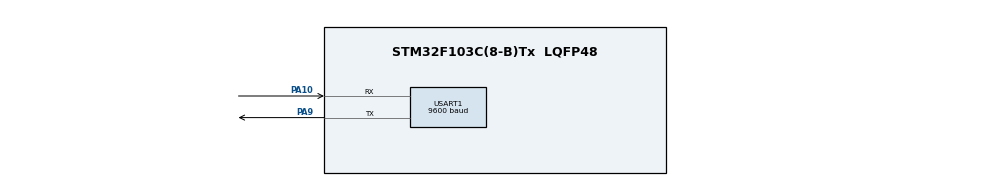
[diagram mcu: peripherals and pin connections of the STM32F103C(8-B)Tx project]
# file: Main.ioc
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Mcu.Family=STM32F1
Mcu.Name=STM32F103C(8-B)Tx
Mcu.Package=LQFP48
NVIC.PriorityGroup=NVIC_PRIORITYGROUP_4
NVIC.USART1_IRQn=true\:0\:0\:false\:false\:true\:true\:true\:true
PA10.Mode=Asynchronous
PA10.Signal=USART1_RX
PA13.Mode=Serial_Wire
PA13.Signal=SYS_JTMS-SWDIO
PA14.Mode=Serial_Wire
PA14.Signal=SYS_JTCK-SWCLK
PA9.Mode=Asynchronous
PA9.Signal=USART1_TX
ProjectManager.HeapSize=0x200
ProjectManager.StackSize=0x400
ProjectManager.TargetToolchain=MDK-ARM V5.27
RCC.APB1Freq_Value=8000000
RCC.APB2Freq_Value=8000000
USART1.BaudRate=9600
USART1.Mode=MODE_TX_RX
USART1.VirtualMode=VM_ASYNC
board=custom

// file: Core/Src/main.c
/* USER CODE BEGIN Header */
/**
  ******************************************************************************
  * @file           : main.c
  * @brief          : Main program body
  ******************************************************************************
  * @attention
  *
  * <h2><center>&copy; Copyright (c) 2021 STMicroelectronics.
  * All rights reserved.</center></h2>
  *
  * This software component is licensed by ST under BSD 3-Clause license,
  * the "License"; You may not use this file except in compliance with the
  * License. You may obtain a copy of the License at:
  *                        opensource.org/licenses/BSD-3-Clause
  *
  ******************************************************************************
  */
/* USER CODE END Header */
#include "main.h"

/* USER CODE BEGIN Includes */
#include <stdio.h>
#include <stm32f1xx_ll_usart_extra.h>
/* USER CODE END Includes */

/* USER CODE BEGIN PV */
//uint8_t i2=0;
uint8_t j=0;
volatile uint8_t task_usart1=0;
char txt[25]= "";
/* USER CODE END PV */

void SystemClock_Config(void);
static void MX_GPIO_Init(void);
static void MX_USART1_UART_Init(void);

int main(void)
{

  /* MCU Configuration--------------------------------------------------------*/

  /* Reset of all peripherals, Initializes the Flash interface and the Systick. */
  LL_APB2_GRP1_EnableClock(LL_APB2_GRP1_PERIPH_AFIO);
  LL_APB1_GRP1_EnableClock(LL_APB1_GRP1_PERIPH_PWR);

  /* System interrupt init*/
  NVIC_SetPriorityGrouping(NVIC_PRIORITYGROUP_4);

  /** NOJTAG: JTAG-DP Disabled and SW-DP Enabled
  */
  LL_GPIO_AF_Remap_SWJ_NOJTAG();

  /* Configure the system clock */
  SystemClock_Config();

  /* Initialize all configured peripherals */
  MX_GPIO_Init();
  MX_USART1_UART_Init();

  /* Infinite loop */
  /* USER CODE BEGIN WHILE */

	LL_USART_EnableIT_RXNE(USART1);
	LL_mDelay(500);

	LL_USART_PutStringFromFlash(USART1, "USART1, Test");

  while(1){
    /* USER CODE END WHILE */

    /* USER CODE BEGIN 3 */
		if(task_usart1==1){
			task_usart1=0;
			LL_USART_PutChar(USART1, '\r');		// 0x0D
			LL_USART_PutChar(USART1, '\n');		// 0x0A
			LL_USART_PutString(USART1, txt);
			for(j=0;j<16;++j){txt[j]=0;};
		}
  }
  /* USER CODE END 3 */
}

void SystemClock_Config(void)
{
  LL_FLASH_SetLatency(LL_FLASH_LATENCY_0);
  while(LL_FLASH_GetLatency()!= LL_FLASH_LATENCY_0)
  {
  }
  LL_RCC_HSI_SetCalibTrimming(16);
  LL_RCC_HSI_Enable();

   /* Wait till HSI is ready */
  while(LL_RCC_HSI_IsReady() != 1)
  {

  }
  LL_RCC_SetAHBPrescaler(LL_RCC_SYSCLK_DIV_1);
  LL_RCC_SetAPB1Prescaler(LL_RCC_APB1_DIV_1);
  LL_RCC_SetAPB2Prescaler(LL_RCC_APB2_DIV_1);
  LL_RCC_SetSysClkSource(LL_RCC_SYS_CLKSOURCE_HSI);

   /* Wait till System clock is ready */
  while(LL_RCC_GetSysClkSource() != LL_RCC_SYS_CLKSOURCE_STATUS_HSI)
  {

  }
  LL_Init1msTick(8000000);
  LL_SetSystemCoreClock(8000000);
}

static void MX_USART1_UART_Init(void)
{

  LL_USART_InitTypeDef USART_InitStruct = {0};

  LL_GPIO_InitTypeDef GPIO_InitStruct = {0};

  /* Peripheral clock enable */
  LL_APB2_GRP1_EnableClock(LL_APB2_GRP1_PERIPH_USART1);

  LL_APB2_GRP1_EnableClock(LL_APB2_GRP1_PERIPH_GPIOA);
  /**USART1 GPIO Configuration
  PA9   ------> USART1_TX
  PA10   ------> USART1_RX
  */
  GPIO_InitStruct.Pin = LL_GPIO_PIN_9;
  GPIO_InitStruct.Mode = LL_GPIO_MODE_ALTERNATE;
  GPIO_InitStruct.Speed = LL_GPIO_SPEED_FREQ_HIGH;
  GPIO_InitStruct.OutputType = LL_GPIO_OUTPUT_PUSHPULL;
  LL_GPIO_Init(GPIOA, &GPIO_InitStruct);

  GPIO_InitStruct.Pin = LL_GPIO_PIN_10;
  GPIO_InitStruct.Mode = LL_GPIO_MODE_FLOATING;
  LL_GPIO_Init(GPIOA, &GPIO_InitStruct);

  /* USART1 interrupt Init */
  NVIC_SetPriority(USART1_IRQn, NVIC_EncodePriority(NVIC_GetPriorityGrouping(),0, 0));
  NVIC_EnableIRQ(USART1_IRQn);

  USART_InitStruct.BaudRate = 9600;
  USART_InitStruct.DataWidth = LL_USART_DATAWIDTH_8B;
  USART_InitStruct.StopBits = LL_USART_STOPBITS_1;
  USART_InitStruct.Parity = LL_USART_PARITY_NONE;
  USART_InitStruct.TransferDirection = LL_USART_DIRECTION_TX_RX;
  USART_InitStruct.HardwareFlowControl = LL_USART_HWCONTROL_NONE;
  USART_InitStruct.OverSampling = LL_USART_OVERSAMPLING_16;
  LL_USART_Init(USART1, &USART_InitStruct);
  LL_USART_ConfigAsyncMode(USART1);
  LL_USART_Enable(USART1);

}

static void MX_GPIO_Init(void)
{

  /* GPIO Ports Clock Enable */
  LL_APB2_GRP1_EnableClock(LL_APB2_GRP1_PERIPH_GPIOA);

}

void Error_Handler(void)
{
}
